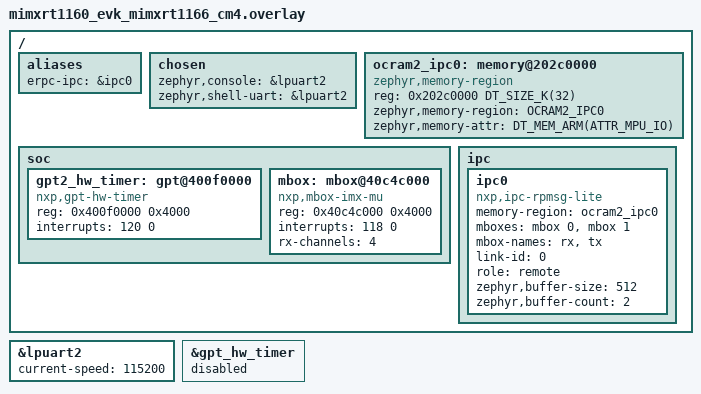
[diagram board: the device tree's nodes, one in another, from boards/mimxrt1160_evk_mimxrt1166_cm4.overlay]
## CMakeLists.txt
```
#
# Copyright 2023-2026 NXP
#
# SPDX-License-Identifier: BSD-3-Clause
#

cmake_minimum_required(VERSION 3.20.0)

find_package(Zephyr REQUIRED HINTS $ENV{ZEPHYR_BASE})

project(remote_server)

message(STATUS "${BOARD} compiles as remote in this sample")

target_include_directories(app PRIVATE ${CMAKE_CURRENT_SOURCE_DIR}/..)

enable_language(C CXX)

target_include_directories(app PRIVATE
    ${PROJECT_SOURCE_DIR}/..
    ${PROJECT_SOURCE_DIR}/src
    ${PROJECT_SOURCE_DIR}/src/service
)

target_sources(app PRIVATE
    # Main files
    ${PROJECT_SOURCE_DIR}/src/main.cpp
    ${PROJECT_SOURCE_DIR}/src/erpc_error_handler.cpp

    # Generated shim code
    ${PROJECT_SOURCE_DIR}/src/service/c_erpc_matrix_multiply_server.cpp
    ${PROJECT_SOURCE_DIR}/src/service/erpc_matrix_multiply_server.cpp
    ${PROJECT_SOURCE_DIR}/src/service/erpc_matrix_multiply_interface.cpp
)

if (CONFIG_BOARD_MIMXRT685_EVK OR CONFIG_BOARD_MIMXRT700_EVK)
    include("${ZEPHYR_BASE}/samples/boards/nxp/adsp/rtxxx/common/remote-dsp-imgs.cmake")
endif()
```

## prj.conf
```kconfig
#
# Copyright 2026 NXP
#
# SPDX-License-Identifier: BSD-3-Clause
#

CONFIG_PRINTK=y

# Compiler
CONFIG_MAIN_STACK_SIZE=4096
CONFIG_HEAP_MEM_POOL_SIZE=8192

# eRPC
CONFIG_ERPC=y
CONFIG_ERPC_TRANSPORT_IPC_SERVICE=y

# RPMSG Lite
CONFIG_RL_API_HAS_ZEROCOPY=y
CONFIG_RL_USE_STATIC_API=y

CONFIG_TIMESLICE_SIZE=1

CONFIG_STDOUT_CONSOLE=n

# CONFIG_INIT_STACKS=y
# CONFIG_NO_OPTIMIZATIONS=y
# CONFIG_DEBUG_THREAD_INFO=y
# CONFIG_THREAD_STACK_INFO=y
```

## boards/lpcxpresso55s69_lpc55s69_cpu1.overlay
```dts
/*
 * Copyright 2026 NXP
 *
 * SPDX-License-Identifier: Apache-2.0
 */

#include <zephyr/dt-bindings/ipc_service/static_vrings.h>
#include <zephyr/dt-bindings/memory-attr/memory-attr-arm.h>

/ {
	aliases {
		erpc-ipc = &ipc0;  /* Select which IPC instance to use for eRPC */
	};

	chosen {
		/* Delete ipc chosen property where old IPM mailbox driver below is
		 * configured.
		 */
		/delete-property/ zephyr,ipc;
		/delete-property/ zephyr,ipc_shm;
	};

	/* Define memory regions for IPC
	 * Note that shared memory must have specific MPU attributes set.
	 */
	sram4_ipc0: memory@20040000 {
		compatible = "zephyr,memory-region", "mmio-sram";
		reg = <0x20040000 DT_SIZE_K(8)>;
		zephyr,memory-region = "SRAM4_IPC0";
		zephyr,memory-attr = <DT_MEM_ARM(ATTR_MPU_IO)>;
	};

	soc {
		/* Delete IPM Driver node nxp,lpc-mailbox */
		/delete-node/ mailbox@8b000;

		/* Attach MBOX driver to Mailbox Unit */
		mbox: mailbox0@5008b000 {
			compatible = "nxp,mbox-mailbox";
			reg = <0x5008b000 0xec>;
			interrupts = <31 0>;
			rx-channels = <4>;
			#mbox-cells = <1>;
			status = "okay";
		};
	};

	ipc {
		/delete-node/ ipc0;

		ipc0: ipc0 {
			compatible = "nxp,ipc-rpmsg-lite";
			memory-region = <&sram4_ipc0>;
			mboxes = <&mbox 0>, <&mbox 1>;
			mbox-names = "rx", "tx";
			link-id = <0>;
			role = "remote";
			zephyr,buffer-size = <512>;
			zephyr,buffer-count = <2>;
			status = "okay";
		};
	};
};
```

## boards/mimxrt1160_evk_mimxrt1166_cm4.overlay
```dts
/*
 * Copyright 2026 NXP
 *
 * SPDX-License-Identifier: Apache-2.0
 */

#include <zephyr/dt-bindings/ipc_service/static_vrings.h>
#include <zephyr/dt-bindings/memory-attr/memory-attr-arm.h>

/ {
	aliases {
		erpc-ipc = &ipc0;  /* Select which IPC instance to use for eRPC */
	};

	chosen {
		zephyr,console = &lpuart2;
		zephyr,shell-uart = &lpuart2;

		/* Delete ipc chosen property where old IPM mailbox driver below is
		 * configured.
		 */
		/delete-property/ zephyr,ipc;
		/delete-property/ zephyr,ipc_shm;
	};

	/* Define memory regions for IPC
	 * Note that shared memory must have specific MPU attributes set.
	 */
	ocram2_ipc0: memory@202c0000 {
		compatible = "zephyr,memory-region", "mmio-sram";
		reg = <0x202c0000 DT_SIZE_K(32)>;
		zephyr,memory-region = "OCRAM2_IPC0";
		zephyr,memory-attr = <DT_MEM_ARM(ATTR_MPU_IO)>;
	};

	soc {
		/delete-node/ gpt@400f0000;

		/* Replace GPT2 with another GPT kernel timer */
		gpt2_hw_timer: gpt@400f0000 {
			compatible = "nxp,gpt-hw-timer";
			reg = <0x400f0000 0x4000>;
			interrupts = <120 0>;
			status = "okay";
		};

		/* Delete IPM Driver node nxp,imx-mu */
		/delete-node/ mailbox@40c4c000;

		/* Attach MBOX driver to MU Unit */
		mbox: mbox@40c4c000 {
			compatible = "nxp,mbox-imx-mu";
			reg = <0x40c4c000 0x4000>;
			interrupts = <118 0>;
			rx-channels = <4>;
			#mbox-cells = <1>;
			status = "okay";
		};
	};

	ipc {
		/delete-node/ ipc0;

		ipc0: ipc0 {
			compatible = "nxp,ipc-rpmsg-lite";
			memory-region = <&ocram2_ipc0>;
			mboxes = <&mbox 0>, <&mbox 1>;
			mbox-names = "rx", "tx";
			link-id = <0>;
			role = "remote";
			zephyr,buffer-size = <512>;
			zephyr,buffer-count = <2>;
			status = "okay";
		};
	};
};

/* Enable secondary LPUART */
&lpuart2 {
	status = "okay";
	current-speed = <115200>;
};

/* Disable primary GPT timer */
&gpt_hw_timer {
	status = "disabled";
};
```

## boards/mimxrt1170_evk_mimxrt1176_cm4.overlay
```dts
/*
 * Copyright 2026 NXP
 *
 * SPDX-License-Identifier: Apache-2.0
 */

#include <zephyr/dt-bindings/ipc_service/static_vrings.h>
#include <zephyr/dt-bindings/memory-attr/memory-attr-arm.h>

/ {
	aliases {
		erpc-ipc = &ipc0;  /* Select which IPC instance to use for eRPC */
	};

	chosen {
		zephyr,flash = &ocram;
		zephyr,console = &lpuart2;
		zephyr,shell-uart = &lpuart2;

		/* Delete ipc chosen property where old IPM mailbox driver bellow is
		 * configured.
		 */
		/delete-property/ zephyr,ipc;
		/delete-property/ zephyr,ipc_shm;
	};

	/* Define memory regions for IPC
	 * Note that shared memory must have specific MPU attributes set.
	 */
	ocram2_ipc0: memory@202c0000{
		compatible = "zephyr,memory-region", "mmio-sram";
		reg = <0x202c0000 DT_SIZE_K(32)>;
		zephyr,memory-region="OCRAM2_IPC0";
		zephyr,memory-attr = <( DT_MEM_ARM(ATTR_MPU_IO))>;
	};

	soc {
		/delete-node/ gpt@400f0000;

		/* Replace GPT2 with another GPT kernel timer */
		gpt2_hw_timer:gpt@400f0000 {
			compatible = "nxp,gpt-hw-timer";
			reg = <0x400f0000 0x4000>;
			interrupts = <120 0>;
			status = "okay";
		};

		/* Delete IPM Driver node nxp,imx-mu */
		/delete-node/ mailbox@40c4c000;

		/* Attach MBOX driver to MU Unit */
		mbox:mbox@40c4c000 {
			compatible = "nxp,mbox-imx-mu";
			reg = <0x40c4c000 0x4000>;
			interrupts = <118 0>;
			rx-channels = <4>;
			#mbox-cells = <1>;
			status = "okay";
		};
	};

	ipc {
		/delete-node/ ipc0;

		ipc0: ipc0 {
			compatible = "nxp,ipc-rpmsg-lite";
			memory-region = <&ocram2_ipc0>;
			/* With ipc-rpmsg-lite we can reuse same MBOX channel per IPC instance */
			mboxes = <&mbox 2>, <&mbox 3>;
			mbox-names = "rx", "tx";
			link-id = <0>;
			role = "remote";
			zephyr,buffer-size = <512>;
			zephyr,buffer-count = <2>;
			status = "okay";
		};
	};
};

/* Enable secondary LPUART */
&lpuart2 {
	status = "okay";
	current-speed = <115200>;
};

/* Disable primary GPT timer */
&gpt_hw_timer {
	status = "disabled";
};
```

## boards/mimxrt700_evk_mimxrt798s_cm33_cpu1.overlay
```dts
/*
 * Copyright 2026 NXP
 *
 * SPDX-License-Identifier: Apache-2.0
 */

#include <zephyr/dt-bindings/ipc_service/static_vrings.h>
#include <zephyr/dt-bindings/memory-attr/memory-attr-arm.h>

/ {
	aliases {
		erpc-ipc = &ipc0;  /* Select which IPC instance to use for eRPC */
	};

	/* Define memory regions for IPC */
	sram1_ipc0: memory@20200000 {
		compatible = "zephyr,memory-region", "mmio-sram";
		reg = <0x20200000 DT_SIZE_K(16)>;
		zephyr,memory-region = "SRAM1_IPC0";
		zephyr,memory-attr = <DT_MEM_ARM(ATTR_MPU_IO)>;
	};

	ipc {
		/delete-node/ ipc0;

		ipc0: ipc0 {
			compatible = "nxp,ipc-rpmsg-lite";
			memory-region = <&sram1_ipc0>;
			mboxes = <&mbox1_b 0>, <&mbox1_b 1>;
			mbox-names = "rx", "tx";
			link-id = <0>;
			role = "remote";
			zephyr,buffer-size = <512>;
			zephyr,buffer-count = <2>;
			status = "okay";
		};
	};
};
```

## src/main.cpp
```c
/*
 * Copyright 2023-2026 NXP
 *
 * SPDX-License-Identifier: BSD-3-Clause
 */

#include <zephyr/kernel.h>

#include "erpc_server_setup.h"
#include "erpc_transport_setup.h"
#include "erpc_matrix_multiply_common.h"
#include "c_erpc_matrix_multiply_server.h"
#include "erpc_error_handler.h"

/*******************************************************************************
 * Definitions
 ******************************************************************************/

/*******************************************************************************
 * Prototypes
 ******************************************************************************/

/*******************************************************************************
 * Code
 ******************************************************************************/

/*!
 * @brief erpcMatrixMultiply function implementation.
 *
 * This is the implementation of the erpcMatrixMultiply function called by the primary core.
 *
 * @param matrix1 First matrix
 * @param matrix2 Second matrix
 * @param result_matrix Result matrix
 */
void erpcMatrixMultiply(Matrix matrix1, Matrix matrix2, Matrix result_matrix)
{
    int32_t i, j, k;

    /* Clear the result matrix */
    for (i = 0; i < matrix_size; ++i)
    {
        for (j = 0; j < matrix_size; ++j)
        {
            result_matrix[i][j] = 0;
        }
    }

    /* Multiply two matrices */
    for (i = 0; i < matrix_size; ++i)
    {
        for (j = 0; j < matrix_size; ++j)
        {
            for (k = 0; k < matrix_size; ++k)
            {
                result_matrix[i][j] += matrix1[i][k] * matrix2[k][j];
            }
        }
    }
}

/*!
 * @brief Main function
 */
int main(void)
{
    erpc_transport_t transport;
    erpc_server_t server;
    erpc_mbf_t message_buffer_factory;
    erpc_service_t service;

    printk("\r\n");
    printk("**************************************************\r\n");
    printk("* eRPC Matrix Multiply Demo - Remote/Slave Core *\r\n");
    printk("**************************************************\r\n");
    printk("\r\n");

    /* Zephyr IPC Service transport layer initialization */
    printk("Initializing Zephyr IPC Service transport...\r\n");
    transport = erpc_transport_zephyr_ipc_remote_init(CONFIG_ERPC_ENDPOINT_NAME, 0);

    if (transport == NULL)
    {
        printk("ERROR: Failed to initialize eRPC transport\r\n");
        return -1;
    }

    printk("Transport initialized successfully\r\n");

    /* MessageBufferFactory initialization - use DYNAMIC, not RPMsg! */
    message_buffer_factory = erpc_mbf_ipc_service_init(transport);
    if (message_buffer_factory == NULL)
    {
        printk("ERROR: Failed to initialize message buffer factory\r\n");
        erpc_transport_zephyr_ipc_remote_deinit(transport);
        return -1;
    }

    /* eRPC server side initialization */
    server = erpc_server_init(transport, message_buffer_factory);
    if (server == NULL)
    {
        printk("ERROR: Failed to initialize eRPC server\r\n");
        erpc_mbf_dynamic_deinit(message_buffer_factory);
        erpc_transport_zephyr_ipc_remote_deinit(transport);
        return -1;
    }

    /* Add the service to the server */
    service = create_MatrixMultiplyService_service();
    if (service == NULL)
    {
        printk("ERROR: Failed to create service\r\n");
        erpc_server_deinit(server);
        erpc_mbf_dynamic_deinit(message_buffer_factory);
        erpc_transport_zephyr_ipc_remote_deinit(transport);
        return -1;
    }

    erpc_add_service_to_server(server, service);

    printk("eRPC server initialized\r\n");
    printk("Ready to receive requests from master core\r\n");
    printk("\r\n");

    for (;;)
    {
        /* Process incoming eRPC messages */
        erpc_status_t status = erpc_server_poll(server);

        /* Handle error status */
        if (status != (erpc_status_t)kErpcStatus_Success)
        {
            /* Print error description */
            printk("ERROR: Server poll failed with status %d\r\n", status);
            erpc_error_handler(status, 0);

            /* Cleanup */
            printk("Cleaning up...\r\n");
            erpc_remove_service_from_server(server, service);
            destroy_MatrixMultiplyService_service(service);
            erpc_server_stop(server);
            erpc_server_deinit(server);
            erpc_mbf_dynamic_deinit(message_buffer_factory);
            erpc_transport_zephyr_ipc_remote_deinit(transport);

            /* Exit program loop */
            break;
        }

        /* Do other tasks while waiting for requests */
        k_yield();
    }

    /* Should not reach here */
    for (;;)
    {
        k_sleep(K_FOREVER);
    }

    return 0;
}
```
